# N32H7xx register map
Vendor: Nationstech Ltd.; File version: 1.0
CPU: CM7 r1p1, little endian, MPU, FPU, 4 interrupt priority bits
Registers are 32-bit, read-write, reset 0x0 unless marked. A register's access mark holds for its fields unless they carry their own. Offsets are from the block's base; [hi:lo] are bit positions; {n}, {i} and the like mark numbered series.

## TCMC — Tightly Coupled Memory Controller
Base 0x5004B000
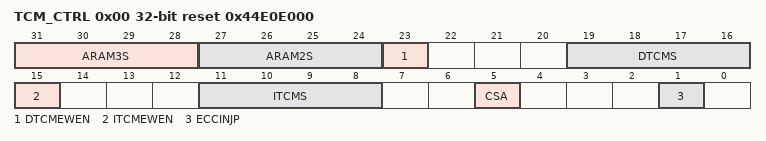
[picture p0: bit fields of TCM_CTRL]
0x00 TCM_CTRL ro reset 0x44E0E000 — TCMC control register
  [31:28] ARAM3S, [27:24] ARAM2S, [23] DTCMEWEN, [19:16] DTCMS, [15] ITCMEWEN, [11:8] ITCMS, [5] CSA, [1] ECCINJP

## JPEGCTRL — JPEG mode CTRL
Base 0x50090800
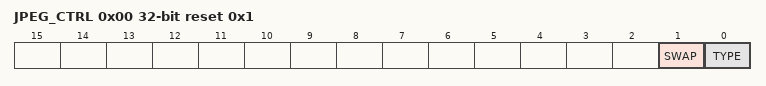
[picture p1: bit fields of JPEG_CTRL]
0x00 JPEG_CTRL reset 0x1 — JPEG mode CTRL
  [1] SWAP, [0] TYPE

## BRC — peripherals to Host
Base 0x50090000
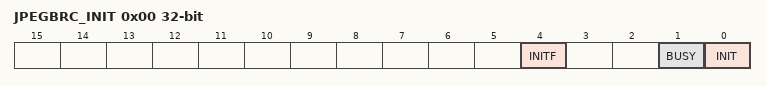
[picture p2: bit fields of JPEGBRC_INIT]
0x00 JPEGBRC_INIT — Core init
  [4] INITF, [1] BUSY, [0] INIT
0x04 JPEGBRC_EN — Core Enable
  [0] EN
0x08 JPEGBRC_BUFBADD — AXI buffer base address
  [31:0] ADDR
0x0C JPEGBRC_BUFSIZE — AXI buffer size
  [15:0] SIZE
0x44 JPEGBRC_USMODE — Up sampling mode
  [1:0] MODE

## RBC — Host to peripherals
Base 0x50070000
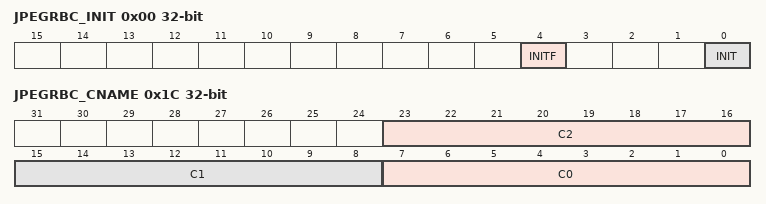
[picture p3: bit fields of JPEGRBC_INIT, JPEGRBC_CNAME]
0x00 JPEGRBC_INIT — Core init
  [4] INITF ro, [0] INIT
0x04 JPEGRBC_EN — Core enable
  [0] EN
0x08 JPEGRBC_SWITCH reset 0x1 — Switch input sample order
  [0] SWITCH
0x0C JPEGRBC_FRMW reset 0x3FFFF — Frame width
  [15:0] WIDTH
0x10 JPEGRBC_FRMH reset 0xFFFF — Frame height
  [15:0] HEIGHT
0x18 JPEGRBC_PFORM — Pixel format
  [2:0] FORMAT
0x1C JPEGRBC_CNAME — Component names
  [23:16] C2, [15:8] C1, [7:0] C0
0x20 JPEGRBC_C0SADD — Component 0 start address
  [31:0] ADDR
0x24 JPEGRBC_C0EADD — Component 0 end address
  [9:0] ADDR
0x60 JPEGRBC_BPS0 — Blocks per Scan 0
  [27:0] NUM
0x64 JPEGRBC_BPS12 — Blocks per Scan 1,2
  [27:0] NUM
0x68 JPEGRBC_ROWS0 — MCU rows Scan 0
  [12:0] NUM
0x6C JPEGRBC_ROWS12 — MCU rows Scan 1,2
  [12:0] ROWS12 — NUM
0x70 JPEGRBC_HHALF — Frame height half
  [14:0] HHALF
0x74 JPEGRBC_BLSS0 — Block line stride Scan 0
  [17:0] SIZE
0x78 JPEGRBC_BLSS12 — Block line stride Scan 1,2
  [17:0] SIZE
0x7C JPEGRBC_BPRS0 — Blocks per MCU row Scan 0
  [14:0] NUM
0x80 JPEGRBC_BPRS12 — Blocks per MCU row Scan 1,2
  [14:0] NUM
0x84 JPEGRBC_MAXW ro reset 0xFFFF — Maximum supported width
  [31:0] WIDTH
0x88 JPEGRBC_MAXH ro reset 0x10000 — Maximum supported height
  [31:0] HEIGHT
0x8C JPEGRBC_MBSIZE ro reset 0xFFFF — Maximum supported buffer size
  [31:0] SIZE

## ENC — Host to peripherals
Base 0x50060000
{0x400+4i} JPEGENC_HUFTAB0_CST_{i} (i=0..31) — JPEGENC_HUFTAB0_CST_{i}
  [31:0] CS
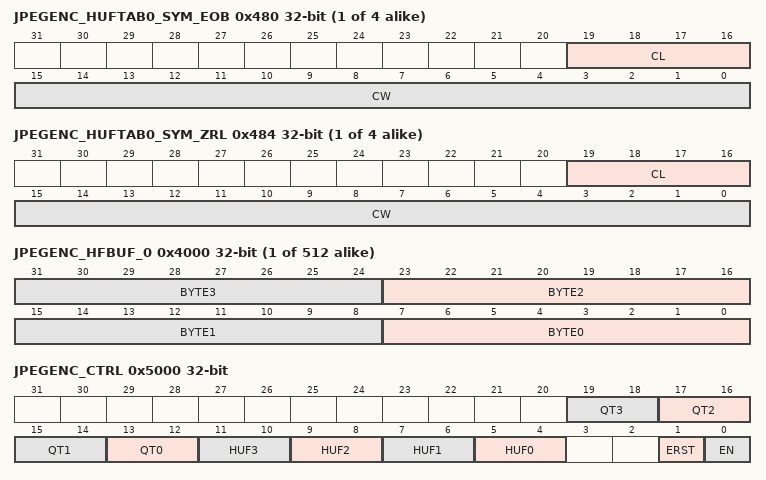
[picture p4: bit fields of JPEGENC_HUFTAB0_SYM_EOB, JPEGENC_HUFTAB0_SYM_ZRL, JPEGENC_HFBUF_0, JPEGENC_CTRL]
{0x480+0x800*i} JPEGENC_HUFTAB{i}_SYM_EOB (i=0..3)
  [19:16] CL, [15:0] CW
{0x484+0x800*i} JPEGENC_HUFTAB{i}_SYM_ZRL (i=0..3)
  [19:16] CL, [15:0] CW
{0xC00+4i} JPEGENC_HUFTAB1_CST_{i} (i=0..31) — JPEGENC_HUFTAB1_CST_{i}
  [31:0] CS
{0x1400+4i} JPEGENC_HUFTAB2_CST_{i} (i=0..31) — JPEGENC_HUFTAB2_CST_{i}
  [31:0] CS
{0x1C00+4i} JPEGENC_HUFTAB3_CST_{i} (i=0..31) — JPEGENC_HUFTAB3_CST_{i}
  [31:0] CS
{0x2000+4i} JPEGENC_QT0_{i} (i=0..63) — JPEGENC_QT0_{i}
  [7:0] QT0
{0x2100+4i} JPEGENC_QT1_{i} (i=0..63) — JPEGENC_QT1_{i}
  [7:0] QT1
{0x2200+4i} JPEGENC_QT2_{i} (i=0..63) — JPEGENC_QT2_{i}
  [7:0] QT2
{0x2300+4i} JPEGENC_QT3_{i} (i=0..63) — JPEGENC_QT3_{i}
  [7:0] QT3
{0x4000+4i} JPEGENC_HFBUF_{i} (i=0..511) — JPEGENC_HFBUF_{i}
  [8n+7:8n] BYTE{n} (n=0..3) — Byte {n} of header word n
0x4800 JPEGENC_HEADD — End address of JPEG header 1st part
  [10:0] ADDR
{0x4814+4i} JPEGENC_HUFTAB{i}E (i=0..3) — End address of Huffman table {i}
  [10:0] ADDR
0x4824 JPEGENC_FEADD — End address of JPEG footer
  [9:0] ADDR
0x5000 JPEGENC_CTRL — Core control register
  [2n+13:2n+12] QT{n} (n=0..3), [2n+5:2n+4] HUF{n} (n=0..3), [1] ERST, [0] EN
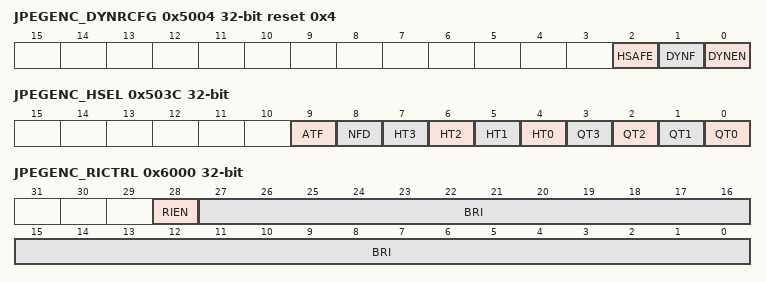
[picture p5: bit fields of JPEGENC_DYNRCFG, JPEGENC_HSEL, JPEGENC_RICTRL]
0x5004 JPEGENC_DYNRCFG reset 0x4 — Dynamic reconfiguration register
  [2] HSAFE, [1] DYNF, [0] DYNEN
0x503C JPEGENC_HSEL — Header parts select
  [9] ATF, [8] NFD, [n+4] HT{n} (n=0..3), [n] QT{n} (n=0..3)
0x5100 JPEGENC_PIPESTS — Status Register Pipe
  [0] OOVF
0x6000 JPEGENC_RICTRL — Restart interval control register
  [28] RIEN, [27:0] BRI
0xA004 JPEGENC_HFSIZE ro reset 0x400 — Header/footer ram size
  [31:0] SIZE
0xA024 JPEGENC_OBSIZE ro reset 0x200 — Output buffer size
  [31:0] OBSIZE — SIZE
